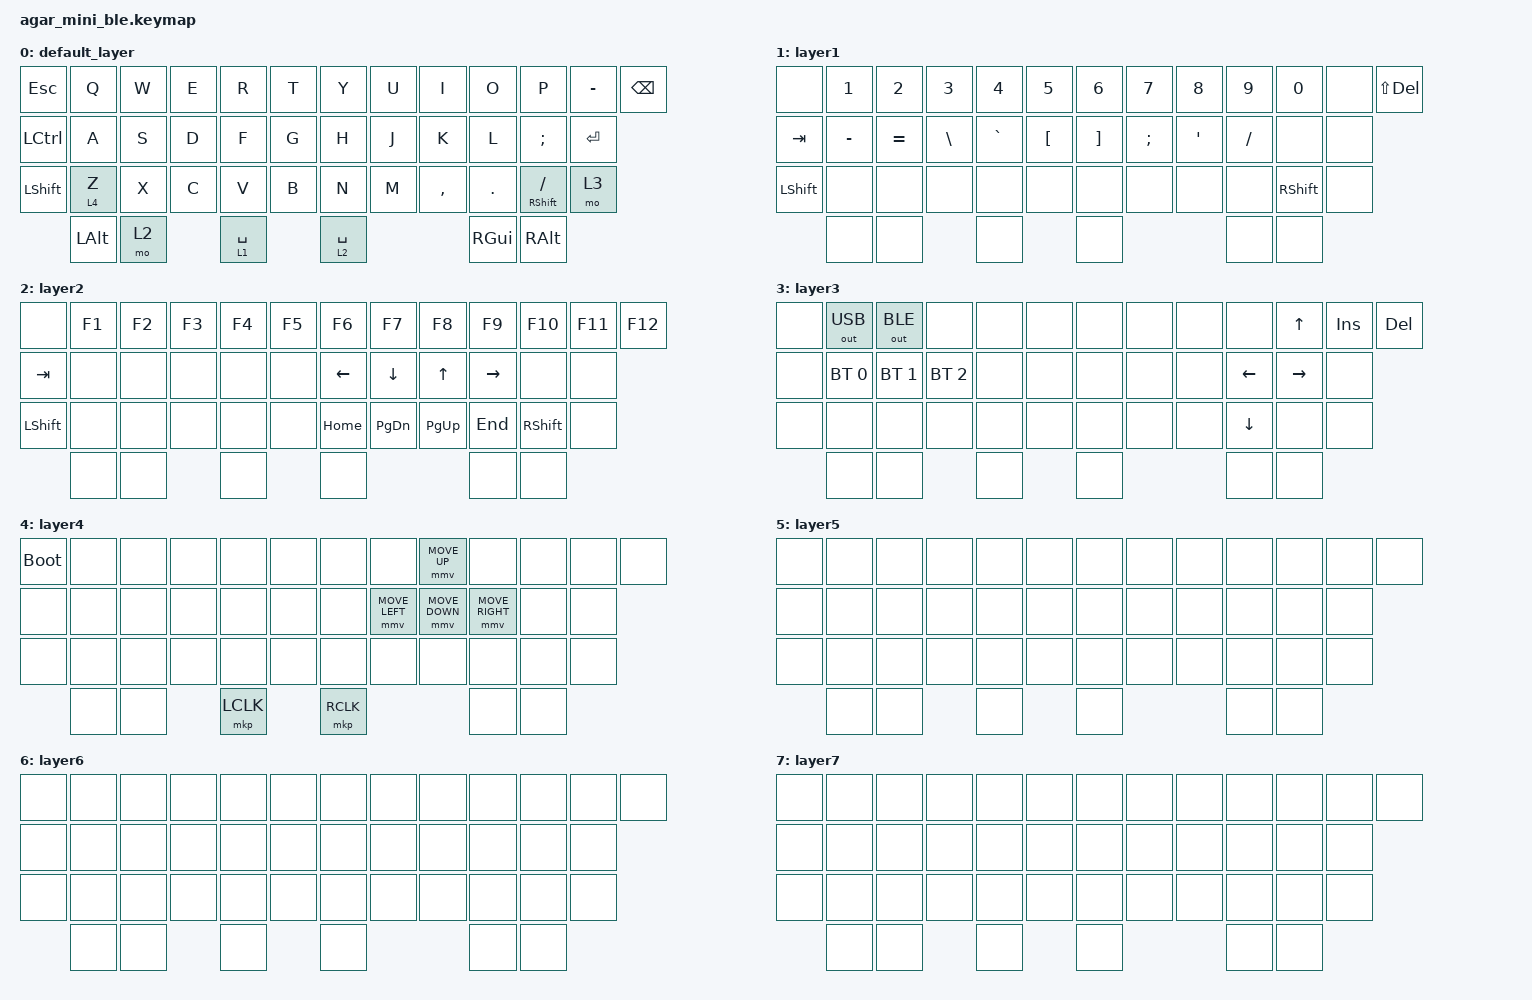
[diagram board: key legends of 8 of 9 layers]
/*
 * Copyright (c) 2021 The ZMK Contributors
 *
 * SPDX-License-Identifier: MIT
 */

#include "./boards/shields/klink_kbd/common.keymap"
#include <behaviors.dtsi>
#include <dt-bindings/zmk/bt.h>
#include <dt-bindings/zmk/keys.h>
#include <dt-bindings/zmk/outputs.h>
#include <dt-bindings/zmk/pointing.h>

/ {
    combos {
        compatible = "zmk,combos";

        eisu {
            bindings = <&kp INTERNATIONAL_5>;
            key-positions = <17 16>;
            layers = <0>;
        };

        henkan {
            bindings = <&kp INTERNATIONAL_4>;
            key-positions = <21 20>;
            layers = <0>;
        };

        minus_underscore {
            bindings = <&kp MINUS>;
            key-positions = <23 22>;
        };
    };

    keymap {
        compatible = "zmk,keymap";

        default_layer {
            bindings = <
&kp ESC           &kp Q         &kp W  &kp E  &kp R        &kp T  &kp Y        &kp U  &kp I      &kp O          &kp P             &kp MINUS  &kp BSPC
&kp LEFT_CONTROL  &kp A         &kp S  &kp D  &kp F        &kp G  &kp H        &kp J  &kp K      &kp L          &kp SEMI          &kp RET
&kp LSHFT         &lt 4 Z       &kp X  &kp C  &kp V        &kp B  &kp N        &kp M  &kp COMMA  &kp DOT        &mt RSHIFT SLASH  &mo 3
                  &kp LEFT_ALT  &mo 2         &lt 1 SPACE         &lt 2 SPACE                    &kp RIGHT_GUI  &kp RIGHT_ALT
            >;
        };

        layer1 {
            bindings = <
&none           &kp N1     &kp N2     &kp N3         &kp N4     &kp N5            &kp N6             &kp N7         &kp N8   &kp N9     &kp N0           &none  &kp LS(DEL)
&kp TAB         &kp MINUS  &kp EQUAL  &kp BACKSLASH  &kp GRAVE  &kp LEFT_BRACKET  &kp RIGHT_BRACKET  &kp SEMICOLON  &kp SQT  &kp SLASH  &none            &none
&kp LEFT_SHIFT  &none      &none      &none          &none      &none             &none              &none          &none    &none      &kp RIGHT_SHIFT  &none
                &none      &none                     &none                        &none                                      &none      &none
            >;
        };

        layer2 {
            bindings = <
&none           &kp F1  &kp F2  &kp F3  &kp F4  &kp F5  &kp F6    &kp F7          &kp F8        &kp F9     &kp F10          &kp F11  &kp F12
&kp TAB         &none   &none   &none   &none   &none   &kp LEFT  &kp DOWN_ARROW  &kp UP_ARROW  &kp RIGHT  &none            &none
&kp LEFT_SHIFT  &none   &none   &none   &none   &none   &kp HOME  &kp PAGE_DOWN   &kp PG_UP     &kp END    &kp RIGHT_SHIFT  &none
                &none   &none           &none           &none                                   &none      &none
            >;
        };

        layer3 {
            bindings = <
&none  &out OUT_USB  &out OUT_BLE  &none         &none  &none  &none  &none  &none  &none           &kp UP_ARROW     &kp INSERT  &kp DELETE
&none  &bt BT_SEL 0  &bt BT_SEL 1  &bt BT_SEL 2  &none  &none  &none  &none  &none  &kp LEFT_ARROW  &kp RIGHT_ARROW  &none
&none  &none         &none         &none         &none  &none  &none  &none  &none  &kp DOWN_ARROW  &none            &none
       &none         &none                       &none         &none                &none           &none
            >;
        };

        layer4 {
            bindings = <
&bootloader  &none  &none  &none  &none      &none  &none      &none           &mmv MOVE_UP    &none            &none  &none  &none
&none        &none  &none  &none  &none      &none  &none      &mmv MOVE_LEFT  &mmv MOVE_DOWN  &mmv MOVE_RIGHT  &none  &none
&none        &none  &none  &none  &none      &none  &none      &none           &none           &none            &none  &none
             &none  &none         &mkp LCLK         &mkp RCLK                                  &none            &none
            >;
        };

        layer5 {
            bindings = <
&none  &none  &none  &none  &none  &none  &none  &none  &none  &none  &none  &none  &none
&none  &none  &none  &none  &none  &none  &none  &none  &none  &none  &none  &none
&none  &none  &none  &none  &none  &none  &none  &none  &none  &none  &none  &none
       &none  &none         &none         &none                &none  &none
            >;
        };

        layer6 {
            bindings = <
&none  &none  &none  &none  &none  &none  &none  &none  &none  &none  &none  &none  &none
&none  &none  &none  &none  &none  &none  &none  &none  &none  &none  &none  &none
&none  &none  &none  &none  &none  &none  &none  &none  &none  &none  &none  &none
       &none  &none         &none         &none                &none  &none
            >;
        };

        layer7 {
            bindings = <
&none  &none  &none  &none  &none  &none  &none  &none  &none  &none  &none  &none  &none
&none  &none  &none  &none  &none  &none  &none  &none  &none  &none  &none  &none
&none  &none  &none  &none  &none  &none  &none  &none  &none  &none  &none  &none
       &none  &none         &none         &none                &none  &none
            >;
        };

        layer_8 {
            bindings = <
&none  &none  &none  &none  &none  &none  &none  &none  &none  &none  &none  &none  &none
&none  &none  &none  &none  &none  &none  &none  &none  &none  &none  &none  &none
&none  &none  &none  &none  &none  &none  &none  &none  &none  &none  &none  &none
       &none  &none         &none         &none                &none  &none         &none
            >;
        };
    };
};
